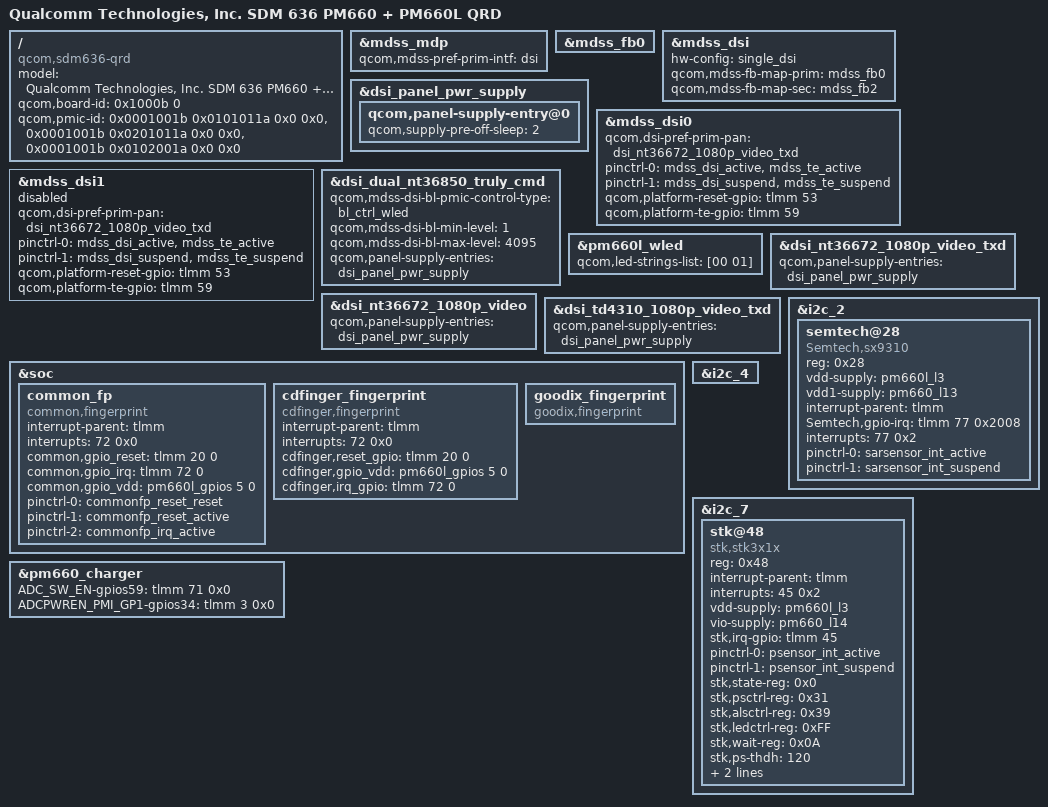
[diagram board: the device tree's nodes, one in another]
/* Copyright (c) 2017, The Linux Foundation. All rights reserved.
 *
 * This program is free software; you can redistribute it and/or modify
 * it under the terms of the GNU General Public License version 2 and
 * only version 2 as published by the Free Software Foundation.
 *
 * This program is distributed in the hope that it will be useful,
 * but WITHOUT ANY WARRANTY; without even the implied warranty of
 * MERCHANTABILITY or FITNESS FOR A PARTICULAR PURPOSE.  See the
 * GNU General Public License for more details.
 */


/dts-v1/;

#include "sdm636.dtsi"
#include "sdm636-qrd.dtsi"
#include "sdm660-internal-codec.dtsi"

#include "X00TD/overlay.dtsi"
#include "X00TD/sdm636-qrd-overlay.dtsi"
#include "X00TD/sdm660-internal-codec-overlay.dtsi"

/ {
	model = "Qualcomm Technologies, Inc. SDM 636 PM660 + PM660L QRD";
	compatible = "qcom,sdm636-qrd", "qcom,sdm636", "qcom,qrd";
	qcom,board-id = <0x1000b 0>;
	qcom,pmic-id = <0x0001001b 0x0101011a 0x0 0x0>,
			<0x0001001b 0x0201011a 0x0 0x0>,
			<0x0001001b 0x0102001a 0x0 0x0>;
};

&mdss_mdp {
	qcom,mdss-pref-prim-intf = "dsi";
};

&mdss_fb0 {
};

&mdss_dsi {
	 hw-config = "single_dsi";
	qcom,mdss-fb-map-prim = <&mdss_fb0>;
	qcom,mdss-fb-map-sec = <&mdss_fb2>;
};

&dsi_panel_pwr_supply {
	qcom,panel-supply-entry@0 {
	qcom,supply-pre-off-sleep = <2>;
	};
};

&mdss_dsi0 {
	qcom,dsi-pref-prim-pan = <&dsi_nt36672_1080p_video_txd>;
	pinctrl-names = "mdss_default", "mdss_sleep";
	pinctrl-0 = <&mdss_dsi_active &mdss_te_active>;
	pinctrl-1 = <&mdss_dsi_suspend &mdss_te_suspend>;
	qcom,platform-reset-gpio = <&tlmm 53 0>;
	qcom,platform-te-gpio = <&tlmm 59 0>;
};

&mdss_dsi1 {
	status = "disabled";
	qcom,dsi-pref-prim-pan = <&dsi_nt36672_1080p_video_txd>;
	pinctrl-names = "mdss_default", "mdss_sleep";
	pinctrl-0 = <&mdss_dsi_active &mdss_te_active>;
	pinctrl-1 = <&mdss_dsi_suspend &mdss_te_suspend>;
	qcom,platform-reset-gpio = <&tlmm 53 0>;
	qcom,platform-te-gpio = <&tlmm 59 0>;
};

&dsi_dual_nt36850_truly_cmd {
	qcom,mdss-dsi-bl-pmic-control-type = "bl_ctrl_wled";
	qcom,mdss-dsi-bl-min-level = <1>;
	qcom,mdss-dsi-bl-max-level = <4095>;
	qcom,panel-supply-entries = <&dsi_panel_pwr_supply>;
};

&pm660l_wled {
	qcom,led-strings-list = [00 01];
};

&dsi_nt36672_1080p_video_txd {
  qcom,panel-supply-entries = <&dsi_panel_pwr_supply>;
};

&dsi_nt36672_1080p_video {
  qcom,panel-supply-entries = <&dsi_panel_pwr_supply>;
};

&dsi_td4310_1080p_video_txd {
	  qcom,panel-supply-entries = <&dsi_panel_pwr_supply>;
};

&soc {
	common_fp {
		compatible = "common,fingerprint";
		interrupt-parent = <&tlmm>;
		interrupts = <72 0x0>;

		common,gpio_reset   = <&tlmm 20 0>;
		common,gpio_irq		= <&tlmm 72 0>;
		common,gpio_vdd		= <&pm660l_gpios 5 0>;
		pinctrl-names		=	"commonfp_reset_reset",
								"commonfp_reset_active",
								"commonfp_irq_active";
		pinctrl-0 = <&commonfp_reset_reset>;
		pinctrl-1 = <&commonfp_reset_active>;
		pinctrl-2 = <&commonfp_irq_active>;
	};

	cdfinger_fingerprint {
		compatible = "cdfinger,fingerprint";
		interrupt-parent = <&tlmm>;
		interrupts = <72 0x0>;
		cdfinger,reset_gpio = <&tlmm 20 0>;
		cdfinger,gpio_vdd  = <&pm660l_gpios 5 0>;
		cdfinger,irq_gpio = <&tlmm 72 0>;
	};

	goodix_fingerprint {
		compatible = "goodix,fingerprint";
	};

};

&i2c_2 { /* BLSP2 */
	status = "okay";
	semtech@28{ /*sar sensor*/
		compatible = "Semtech,sx9310";
		reg = <0x28>;
		vdd-supply  =<&pm660l_l3>;
		vdd1-supply =<&pm660_l13>;  // for svdd
		interrupt-parent = <&tlmm>;
		Semtech,gpio-irq= <&tlmm 77 0x2008>; // gpio 77
		interrupts = <77 0x2>;
		pinctrl-names = "sarsensor_active", "sarsensor_suspend";
		pinctrl-0 = <&sarsensor_int_active>;
		pinctrl-1 = <&sarsensor_int_suspend>;
	};
};

&i2c_4 {	
		status = "okay";
};

&i2c_7 { /* for P/L Sensor */
	status = "okay";
	stk@48 {
		compatible = "stk,stk3x1x";
		reg = <0x48>;
		interrupt-parent = <&tlmm>;
		interrupts = <45 0x2>;
		vdd-supply = <&pm660l_l3>;
		vio-supply = <&pm660_l14>;
		stk,irq-gpio = <&tlmm 45 0x02>;
		pinctrl-names = "psensor_active", "psensor_suspend";
		pinctrl-0 = <&psensor_int_active>;
		pinctrl-1 = <&psensor_int_suspend>;
		stk,state-reg = <0x0>;
		stk,psctrl-reg = <0x31>;
		stk,alsctrl-reg = <0x39>;
		stk,ledctrl-reg = <0xFF>;
		stk,wait-reg = <0x0A>;
		stk,ps-thdh = <120>;
		stk,ps-thdl = <90>;
		stk,transmittance = <1100>;
	};
};

&pm660_charger {
       ADC_SW_EN-gpios59 = <&tlmm 71 0x0>;
       ADCPWREN_PMI_GP1-gpios34 = <&tlmm 3 0x0>;
};
